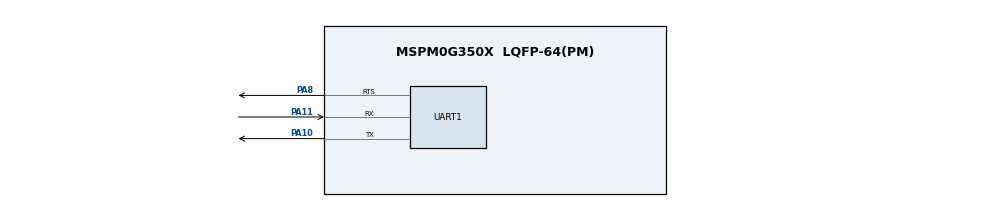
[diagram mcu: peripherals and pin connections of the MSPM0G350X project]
  // @cliArgs --device "MSPM0G350X" --package "LQFP-64(PM)" --part "Default"
// @cliArgs --board /ti/boards/LP_MSPM0G3507 --rtos nortos

/**
 * Import the modules used in this configuration.
 */
const Board  = scripting.addModule("/ti/driverlib/Board");
const GPIO   = scripting.addModule("/ti/driverlib/GPIO", {}, false);
const GPIO1  = GPIO.addInstance();
const GPIO2  = GPIO.addInstance();
const SYSCTL = scripting.addModule("/ti/driverlib/SYSCTL");
const UART   = scripting.addModule("/ti/driverlib/UART", {}, false);
const UART1  = UART.addInstance();

/**
 * Write custom configuration values to the imported modules.
 */

GPIO1.$name                                 = "GPIO_DE_TX";
GPIO1.associatedPins[0].assignedPort        = "PORTB";
GPIO1.associatedPins[0].assignedPortSegment = "Lower";
GPIO1.associatedPins[0].assignedPin         = "4";
GPIO1.associatedPins[0].$name               = "TRANSMITTER";

GPIO2.$name                          = "GPIO_LEDS";
GPIO2.associatedPins[0].assignedPort = "PORTA";
GPIO2.associatedPins[0].assignedPin  = "0";
GPIO2.associatedPins[0].$name        = "USER_LED_1";

SYSCTL.forceDefaultClkConfig = true;
SYSCTL.clockTreeEn  = true;

UART1.$name                     = "UART_0";
UART1.flowControl               = "RTS";
UART1.enableFIFO                = true;
UART1.uartMode                  = "RS485";
UART1.peripheral.$assign        = "UART0";
UART1.peripheral.rxPin.$assign  = "PA11";
UART1.peripheral.txPin.$assign  = "PA10";
UART1.peripheral.rtsPin.$assign = "PA8";
